# f28004x_dev_cfg_regs register map
Vendor: Texas Instruments
Peripheral module from a debugger description file (folder C2000).
Address unit: 16 bits
Registers are 32-bit, access not given, no defined reset value unless marked. A register's access mark holds for its fields unless they carry their own. Offsets are as the file gives them; lines under a group give offsets from that group; [hi:lo] are bit positions; {n}, {i} and the like mark numbered series; 'fields as' and 'values as' point back to an identical list; <NAME> marks a mode.

## DEV_CFG_REGS — DEV CFG Registers
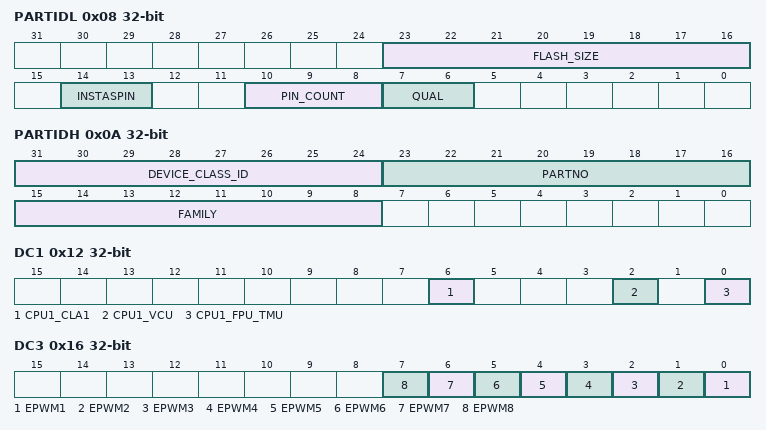
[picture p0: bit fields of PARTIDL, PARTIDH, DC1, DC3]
0x08 PARTIDL — Lower 32-bit of Device PART Identification Number
  [23:16] FLASH_SIZE — Flash size in KB (access R/WOnce)
  [14:13] INSTASPIN — Instaspin feature set (access R/WOnce)
  [10:8] PIN_COUNT — Device Pin Count (access R/WOnce)
  [7:6] QUAL — Qualification Status (access R/WOnce)
0x0A PARTIDH — Upper 32-bit of Device PART Identification Number
  [31:24] DEVICE_CLASS_ID ro
  [23:16] PARTNO — Device part number (access R/WOnce)
  [15:8] FAMILY — Device family (access R/WOnce)
0x0C REVID ro — Device Revision Number
  [15:0] REVID — Device Revision ID. This is specific to the Device
0x10 DC0 — Device Capability: Device Information
0x12 DC1 — Device Capability: Processing Block Customization
  [6] CPU1_CLA1 — CLA1 (access R/WOnce)
  [2] CPU1_VCU — CPU1's VCU (access R/WOnce)
  [0] CPU1_FPU_TMU — CPU1's FPU1+TMU1 (access R/WOnce)
0x14 DC2 — Device Capability: EMIF Customization
0x16 DC3 — Device Capability: Peripheral Customization
  [n-1] EPWM{n} (n=1..8) — EPWM{n} Present (access R/WOnce)
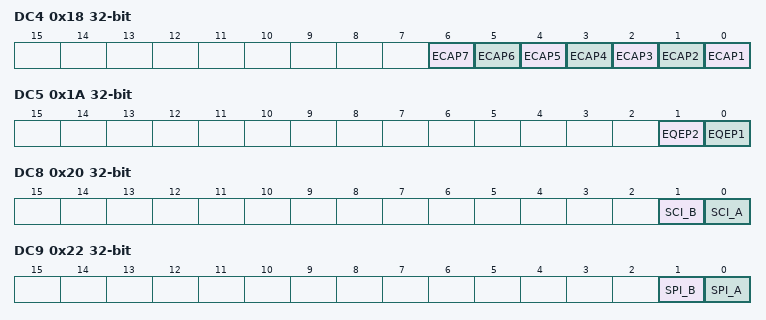
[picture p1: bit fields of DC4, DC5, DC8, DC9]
0x18 DC4 — Device Capability: Peripheral Customization
  [n-1] ECAP{n} (n=1..7) — ECAP{n} Present (access R/WOnce)
0x1A DC5 — Device Capability: Peripheral Customization
  [1] EQEP2 — EQEP2 Present (access R/WOnce)
  [0] EQEP1 — EQEP1 Present (access R/WOnce)
0x1C DC6 — Device Capability: Peripheral Customization
0x1E DC7 — Device Capability: Peripheral Customization
  [0] SD1 — SD1 Present (access R/WOnce)
0x20 DC8 — Device Capability: Peripheral Customization
  [1] SCI_B — SCI_B Present (access R/WOnce)
  [0] SCI_A — SCI_A Present (access R/WOnce)
0x22 DC9 — Device Capability: Peripheral Customization
  [1] SPI_B — SPI_B Present (access R/WOnce)
  [0] SPI_A — SPI_A Present (access R/WOnce)
0x24 DC10 — Device Capability: Peripheral Customization
  [0] I2C_A — I2C_A Present (access R/WOnce)
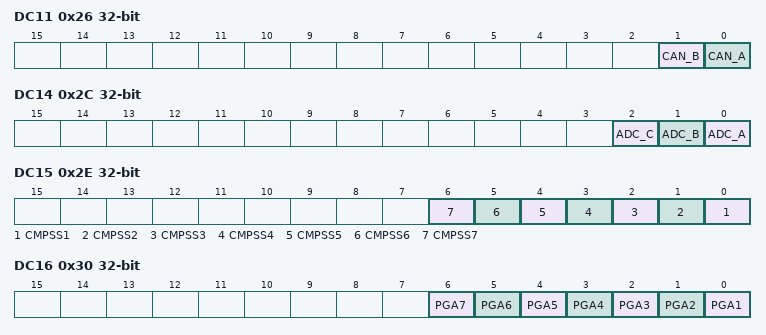
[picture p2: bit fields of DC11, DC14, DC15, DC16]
0x26 DC11 — Device Capability: Peripheral Customization
  [1] CAN_B — CAN_B Present (access R/WOnce)
  [0] CAN_A — CAN_A Present (access R/WOnce)
0x28 DC12 — Device Capability: Peripheral Customization
0x2A DC13 — Device Capability: Peripheral Customization
0x2C DC14 — Device Capability: Analog Modules Customization
  [2] ADC_C — ADC_C Present (access R/WOnce)
  [1] ADC_B — ADC_B Present (access R/WOnce)
  [0] ADC_A — ADC_A Present (access R/WOnce)
0x2E DC15 — Device Capability: Analog Modules Customization
  [n-1] CMPSS{n} (n=1..7) — CMPSS{n} Present (access R/WOnce)
0x30 DC16 — Device Capability: Analog Modules Customization
  [n-1] PGA{n} (n=1..7) — PGA{n} Present (access R/WOnce)
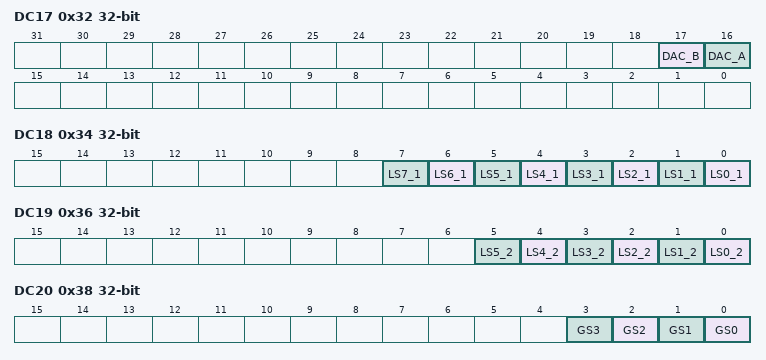
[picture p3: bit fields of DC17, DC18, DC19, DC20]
0x32 DC17 — Device Capability: Analog Modules Customization
  [17] DAC_B — Buffered-DAC_B (access R/WOnce)
  [16] DAC_A — Buffered-DAC_A (access R/WOnce)
0x34 DC18 — Device Capability: Lx.1 SRAM Customization
  [n] LS{n}_1 (n=0..7) — LS{n}_1 Present (access R/WOnce)
0x36 DC19 — Device Capability: Lx.2 SRAM Customization
  [n] LS{n}_2 (n=0..5) — LS{n}_2 Present (access R/WOnce)
0x38 DC20 — Device Capability: GSx SRAM Customization
  [n] GS{n} (n=0..3) — GS{n} Present (access R/WOnce)
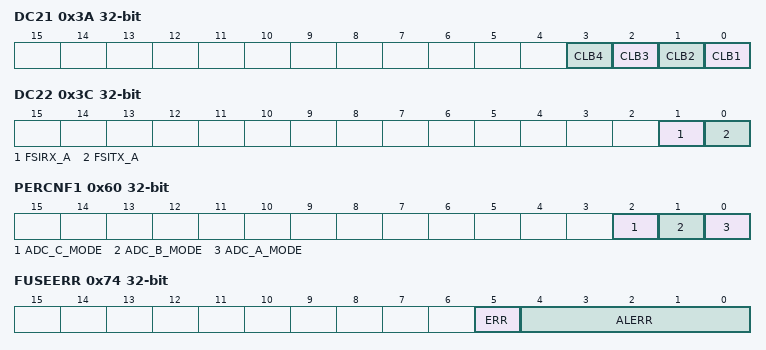
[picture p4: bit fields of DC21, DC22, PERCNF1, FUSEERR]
0x3A DC21 — Device Capability: CLB
  [n-1] CLB{n} (n=1..4) — CLB{n} Present (access R/WOnce)
0x3C DC22 — Device Capability: FSI
  [1] FSIRX_A — FSIRX_A Present (access R/WOnce)
  [0] FSITX_A — FSITX_A Present (access R/WOnce)
0x3E DC23 — Device Capability: LIN
  [0] LIN_A — LIN_A Present (access R/WOnce)
0x40 DC24 — Device Capability: PMBUS
  [0] PMBUS_A — PMBUS_A Present (access R/WOnce)
0x42 DC25 — Device Capability: DCC
0x60 PERCNF1 — Peripheral Configuration register
  [2] ADC_C_MODE — ADC_C mode setting bit (access R/WOnce)
  [1] ADC_B_MODE — ADC_B mode setting bit (access R/WOnce)
  [0] ADC_A_MODE — ADC_A mode setting bit (access R/WOnce)
0x74 FUSEERR ro — e-Fuse error Status register
  [5] ERR — Efuse Self Test Error Status
  [4:0] ALERR — Efuse Autoload Error Status
0x82 SOFTPRES0 rw — Processing Block Software Reset register
  [0] CPU1_CLA1 — CPU1_CLA1 software reset bit
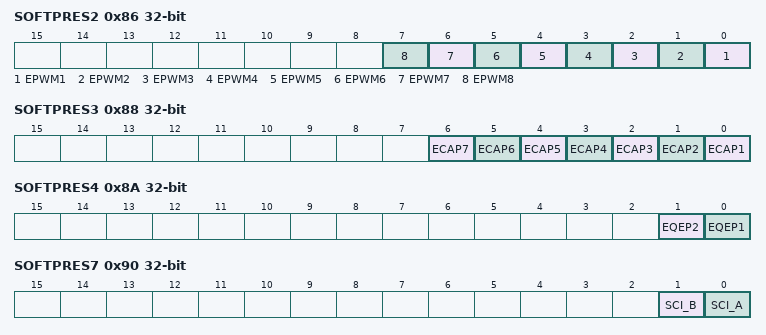
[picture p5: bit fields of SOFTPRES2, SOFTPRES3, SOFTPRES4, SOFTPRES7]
0x86 SOFTPRES2 rw — Peripheral Software Reset register
  [n-1] EPWM{n} (n=1..8) — EPWM{n} software reset bit
0x88 SOFTPRES3 rw — Peripheral Software Reset register
  [n-1] ECAP{n} (n=1..7) — ECAP{n} software reset bit
0x8A SOFTPRES4 rw — Peripheral Software Reset register
  [1] EQEP2 — EQEP2 software reset bit
  [0] EQEP1 — EQEP1 software reset bit
0x8E SOFTPRES6 rw — Peripheral Software Reset register
  [0] SD1 — SD1 software reset bit
0x90 SOFTPRES7 rw — Peripheral Software Reset register
  [1] SCI_B — SCI_B software reset bit
  [0] SCI_A — SCI_A software reset bit
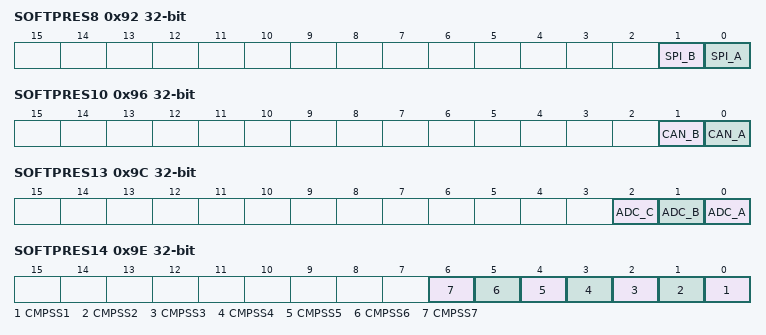
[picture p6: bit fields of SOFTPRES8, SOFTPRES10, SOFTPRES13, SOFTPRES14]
0x92 SOFTPRES8 rw — Peripheral Software Reset register
  [1] SPI_B — SPI_B software reset bit
  [0] SPI_A — SPI_A software reset bit
0x94 SOFTPRES9 rw — Peripheral Software Reset register
  [0] I2C_A — I2C_A software reset bit
0x96 SOFTPRES10 rw — Peripheral Software Reset register
  [1] CAN_B — CAN_B software reset bit
  [0] CAN_A — CAN_A software reset bit
0x9C SOFTPRES13 rw — Peripheral Software Reset register
  [2] ADC_C — ADC_C software reset bit
  [1] ADC_B — ADC_B software reset bit
  [0] ADC_A — ADC_A software reset bit
0x9E SOFTPRES14 rw — Peripheral Software Reset register
  [n-1] CMPSS{n} (n=1..7) — CMPSS{n} software reset bit
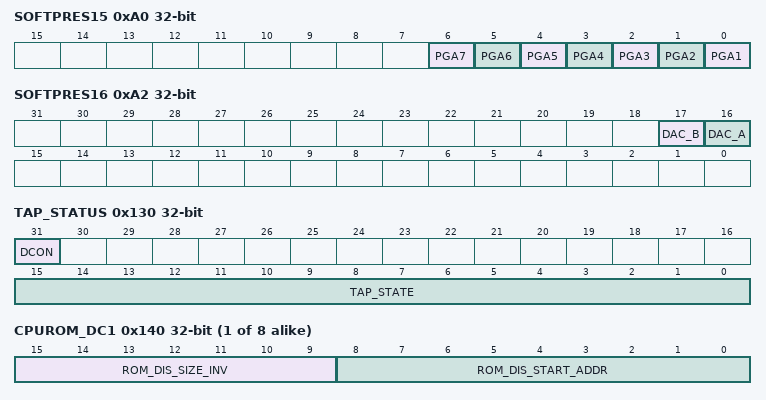
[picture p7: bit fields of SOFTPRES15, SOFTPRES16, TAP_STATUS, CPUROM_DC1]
0xA0 SOFTPRES15 rw — Peripheral Software Reset register
  [n-1] PGA{n} (n=1..7) — PGA{n} software reset bit
0xA2 SOFTPRES16 rw — Peripheral Software Reset register
  [17] DAC_B — Buffered_DAC_B software reset bit
  [16] DAC_A — Buffered_DAC_A software reset bit
0xA4 SOFTPRES17 — Peripheral Software Reset register
0xA6 SOFTPRES18 — Peripheral Software Reset register
0xA8 SOFTPRES19 rw — Peripheral Software Reset register
  [0] LIN_A — LIN_A software reset bit
0xAA SOFTPRES20 rw — Peripheral Software Reset register
  [0] PMBUS_A — PMBUS_A software reset bit
0xAC SOFTPRES21 — Peripheral Software Reset register
0x12E PKGTYPE — Package type info. for internal connections/programming
  [3:0] PKGTYPE — Package and Bond Type Qualifier (access R/WOnce)
0x130 TAP_STATUS ro — Status of JTAG State machine and Debugger Connect
  [31] DCON — Debugger Connect Indication
  [15:0] TAP_STATE — Present TAP State
{0x13E+2i} CPUROM_DC{i} (i=1..8) — Device Capabiity registers for ROM
  [15:9] ROM_DIS_SIZE_INV — Size(Inverted) of ROM section disabled (access R/WOnce)
  [8:0] ROM_DIS_START_ADDR — Start Address of disabled ROM (access R/WOnce)
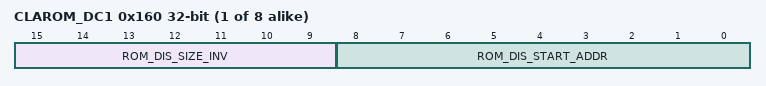
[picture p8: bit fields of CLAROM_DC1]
{0x15E+2i} CLAROM_DC{i} (i=1..8) — Device Capabiity registers for ROM
  fields as CPUROM_DC1
